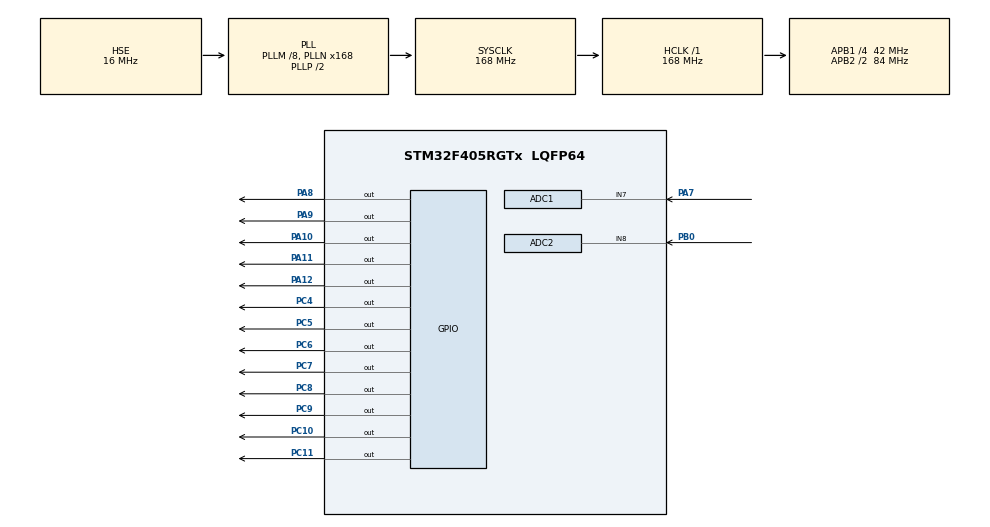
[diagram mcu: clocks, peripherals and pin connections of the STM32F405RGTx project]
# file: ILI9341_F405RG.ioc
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ADC1.Channel-0\#ChannelRegularConversion=ADC_CHANNEL_7
ADC1.NbrOfConversionFlag=1
ADC1.Rank-0\#ChannelRegularConversion=1
ADC1.SamplingTime-0\#ChannelRegularConversion=ADC_SAMPLETIME_3CYCLES
ADC1.master=1
ADC2.Channel-0\#ChannelRegularConversion=ADC_CHANNEL_8
ADC2.NbrOfConversionFlag=1
ADC2.Rank-0\#ChannelRegularConversion=1
ADC2.SamplingTime-0\#ChannelRegularConversion=ADC_SAMPLETIME_3CYCLES
Mcu.Family=STM32F4
Mcu.Name=STM32F405RGTx
Mcu.Package=LQFP64
NVIC.PriorityGroup=NVIC_PRIORITYGROUP_4
NVIC.TIM1_UP_TIM10_IRQn=true\:0\:0\:false\:false\:true\:true\:true
NVIC.TIM2_IRQn=true\:0\:0\:false\:false\:true\:true\:true
PA10.GPIO_Speed=GPIO_SPEED_FREQ_MEDIUM
PA10.PinState=GPIO_PIN_SET
PA10.Signal=GPIO_Output
PA11.GPIO_Speed=GPIO_SPEED_FREQ_MEDIUM
PA11.PinState=GPIO_PIN_SET
PA11.Signal=GPIO_Output
PA12.GPIO_Speed=GPIO_SPEED_FREQ_MEDIUM
PA12.PinState=GPIO_PIN_SET
PA12.Signal=GPIO_Output
PA13.Mode=Trace_Asynchronous_SW
PA13.Signal=SYS_JTMS-SWDIO
PA14.Mode=Trace_Asynchronous_SW
PA14.Signal=SYS_JTCK-SWCLK
PA7.Signal=ADCx_IN7
PA8.GPIO_Speed=GPIO_SPEED_FREQ_MEDIUM
PA8.PinState=GPIO_PIN_SET
PA8.Signal=GPIO_Output
PA9.GPIO_Speed=GPIO_SPEED_FREQ_MEDIUM
PA9.PinState=GPIO_PIN_SET
PA9.Signal=GPIO_Output
PB0.Signal=ADCx_IN8
PB3.Mode=Trace_Asynchronous_SW
PB3.Signal=SYS_JTDO-SWO
PC10.GPIO_Speed=GPIO_SPEED_FREQ_MEDIUM
PC10.Signal=GPIO_Output
PC11.GPIO_Speed=GPIO_SPEED_FREQ_MEDIUM
PC11.Signal=GPIO_Output
PC4.GPIO_Speed=GPIO_SPEED_FREQ_MEDIUM
PC4.Signal=GPIO_Output
PC5.GPIO_Speed=GPIO_SPEED_FREQ_MEDIUM
PC5.Signal=GPIO_Output
PC6.GPIO_Speed=GPIO_SPEED_FREQ_MEDIUM
PC6.Signal=GPIO_Output
PC7.GPIO_Speed=GPIO_SPEED_FREQ_MEDIUM
PC7.Signal=GPIO_Output
PC8.GPIO_Speed=GPIO_SPEED_FREQ_MEDIUM
PC8.Signal=GPIO_Output
PC9.GPIO_Speed=GPIO_SPEED_FREQ_MEDIUM
PC9.Signal=GPIO_Output
PH0-OSC_IN.Mode=HSE-External-Oscillator
PH0-OSC_IN.Signal=RCC_OSC_IN
PH1-OSC_OUT.Mode=HSE-External-Oscillator
PH1-OSC_OUT.Signal=RCC_OSC_OUT
ProjectManager.HeapSize=0x800
ProjectManager.StackSize=0x400
ProjectManager.TargetToolchain=STM32CubeIDE
RCC.48MHZClocksFreq_Value=84000000
RCC.AHBFreq_Value=168000000
RCC.APB1CLKDivider=RCC_HCLK_DIV4
RCC.APB1Freq_Value=42000000
RCC.APB1TimFreq_Value=84000000
RCC.APB2CLKDivider=RCC_HCLK_DIV2
RCC.APB2Freq_Value=84000000
RCC.APB2TimFreq_Value=168000000
RCC.CortexFreq_Value=168000000
RCC.HCLKFreq_Value=168000000
RCC.HSE_VALUE=16000000
RCC.HSI_VALUE=16000000
RCC.LSE_VALUE=32768
RCC.PLLM=8
RCC.PLLN=168
RCC.PLLSourceVirtual=RCC_PLLSOURCE_HSE
RCC.SYSCLKFreq_VALUE=168000000
RCC.SYSCLKSource=RCC_SYSCLKSOURCE_PLLCLK
RCC.VCOOutputFreq_Value=336000000
SH.ADCx_IN7.0=ADC1_IN7,IN7
SH.ADCx_IN8.0=ADC2_IN8,IN8
TIM10.Prescaler=84 - 1
TIM2.Prescaler=84 - 1
VP_TIM10_VS_ClockSourceINT.Mode=Enable_Timer
VP_TIM2_VS_ClockSourceINT.Mode=Internal
board=custom

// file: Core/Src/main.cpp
/* USER CODE BEGIN Header */
/**
 ******************************************************************************
 * @file           : main.c
 * @brief          : Main program body
 ******************************************************************************
 * @attention
 *
 * <h2><center>&copy; Copyright (c) 2021 STMicroelectronics.
 * All rights reserved.</center></h2>
 *
 * This software component is licensed by ST under BSD 3-Clause license,
 * the "License"; You may not use this file except in compliance with the
 * License. You may obtain a copy of the License at:
 *                        opensource.org/licenses/BSD-3-Clause
 *
 ******************************************************************************
 */
/* USER CODE END Header */
#include "main.h"
#include "adc.h"
#include "tim.h"
#include "gpio.h"

/* USER CODE BEGIN Includes */
#include "ILI9341.h"
#include "Flash_Icons.h"
#include <stdio.h>
/* USER CODE END Includes */

void SystemClock_Config(void);

int main(void)
{

    /* MCU Configuration--------------------------------------------------------*/

    /* Reset of all peripherals, Initializes the Flash interface and the Systick. */
    HAL_Init();

    /* Configure the system clock */
    SystemClock_Config();

    /* Initialize all configured peripherals */
    MX_GPIO_Init();
    MX_TIM2_Init();
    MX_TIM10_Init();
    MX_ADC1_Init();
    MX_ADC2_Init();
    /* USER CODE BEGIN 2 */

    ILI9341::Reset();
    ILI9341::Init();
    ILI9341::SetRotation(0);

    ILI9341::Fill(COLOR_WHITE);

    uint16_t x0 = (ILI9341::_width - 128) / 2;
    uint16_t gap = (ILI9341::_height - 2 * 128) / 3;
    uint16_t y0 = gap;

    ILI9341::Image(x0, y0, pcbIcon_w, pcbIcon_h, pcbIcon, pcbIcon_size);
    y0 += 128 + gap;
    ILI9341::Image(x0, y0, thermometerIcon_w, thermometerIcon_h, thermometerIcon,
            thermometerIcon_size);

    /* USER CODE END 2 */

    /* Infinite loop */
    while (1)
    {

    }
}

void SystemClock_Config(void)
{
    RCC_OscInitTypeDef RCC_OscInitStruct =
        { 0 };
    RCC_ClkInitTypeDef RCC_ClkInitStruct =
        { 0 };

    /** Configure the main internal regulator output voltage
     */
    __HAL_RCC_PWR_CLK_ENABLE();
    __HAL_PWR_VOLTAGESCALING_CONFIG(PWR_REGULATOR_VOLTAGE_SCALE1);
    /** Initializes the RCC Oscillators according to the specified parameters
     * in the RCC_OscInitTypeDef structure.
     */
    RCC_OscInitStruct.OscillatorType = RCC_OSCILLATORTYPE_HSE;
    RCC_OscInitStruct.HSEState = RCC_HSE_ON;
    RCC_OscInitStruct.PLL.PLLState = RCC_PLL_ON;
    RCC_OscInitStruct.PLL.PLLSource = RCC_PLLSOURCE_HSE;
    RCC_OscInitStruct.PLL.PLLM = 8;
    RCC_OscInitStruct.PLL.PLLN = 168;
    RCC_OscInitStruct.PLL.PLLP = RCC_PLLP_DIV2;
    RCC_OscInitStruct.PLL.PLLQ = 4;
    if (HAL_RCC_OscConfig(&RCC_OscInitStruct) != HAL_OK)
    {
        Error_Handler();
    }
    /** Initializes the CPU, AHB and APB buses clocks
     */
    RCC_ClkInitStruct.ClockType = RCC_CLOCKTYPE_HCLK | RCC_CLOCKTYPE_SYSCLK | RCC_CLOCKTYPE_PCLK1
            | RCC_CLOCKTYPE_PCLK2;
    RCC_ClkInitStruct.SYSCLKSource = RCC_SYSCLKSOURCE_PLLCLK;
    RCC_ClkInitStruct.AHBCLKDivider = RCC_SYSCLK_DIV1;
    RCC_ClkInitStruct.APB1CLKDivider = RCC_HCLK_DIV4;
    RCC_ClkInitStruct.APB2CLKDivider = RCC_HCLK_DIV2;

    if (HAL_RCC_ClockConfig(&RCC_ClkInitStruct, FLASH_LATENCY_5) != HAL_OK)
    {
        Error_Handler();
    }
}

void Error_Handler(void)
{
}

/************************ (C) COPYRIGHT STMicroelectronics *****END OF FILE****/
